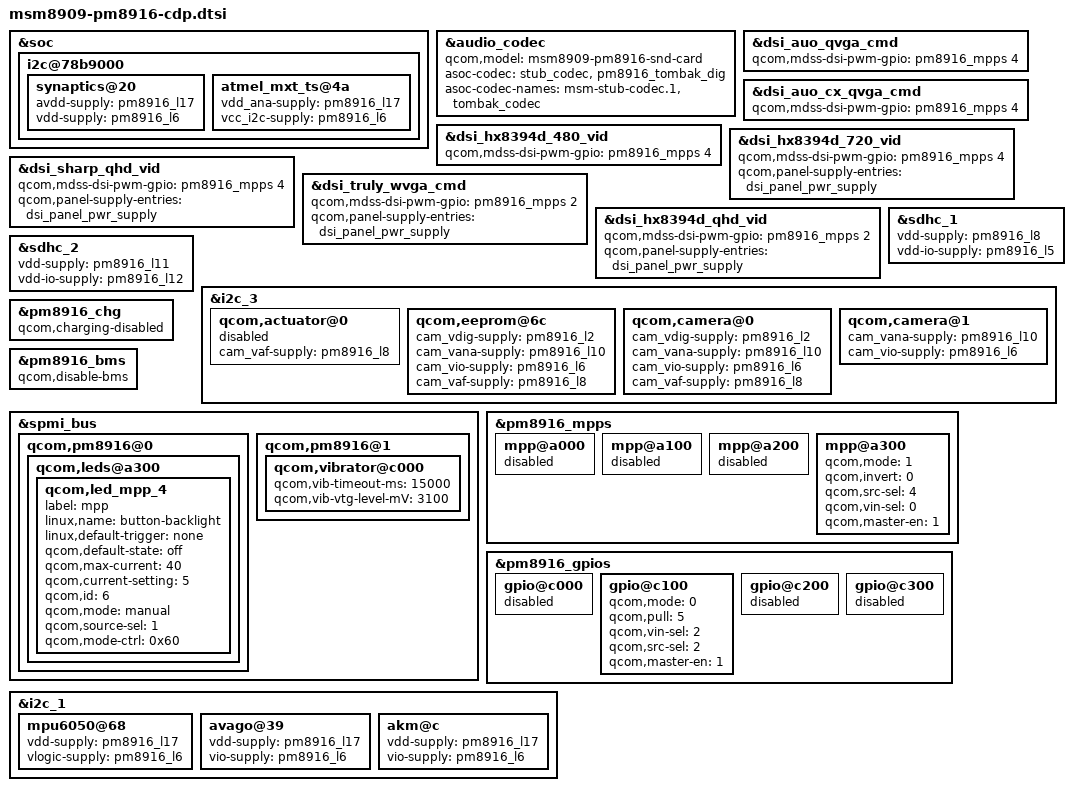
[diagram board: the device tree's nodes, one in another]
/*
 * Copyright (c) 2014-2016, 2017, The Linux Foundation. All rights reserved.
 *
 * This program is free software; you can redistribute it and/or modify
 * it under the terms of the GNU General Public License version 2 and
 * only version 2 as published by the Free Software Foundation.
 *
 * This program is distributed in the hope that it will be useful,
 * but WITHOUT ANY WARRANTY; without even the implied warranty of
 * MERCHANTABILITY or FITNESS FOR A PARTICULAR PURPOSE.  See the
 * GNU General Public License for more details.
 */

#include "msm8909-pm8916.dtsi"
#include "msm8909-pinctrl.dtsi"

&soc {
	i2c@78b9000 {
		synaptics@20 {
			avdd-supply = <&pm8916_l17>;
			vdd-supply = <&pm8916_l6>;
		};

		atmel_mxt_ts@4a {
			vdd_ana-supply = <&pm8916_l17>;
			vcc_i2c-supply = <&pm8916_l6>;
		};
	};

};

&audio_codec {
	status = "ok";
	qcom,model = "msm8909-pm8916-snd-card";
	asoc-codec = <&stub_codec>, <&pm8916_tombak_dig>;
	asoc-codec-names = "msm-stub-codec.1", "tombak_codec";
};

&dsi_auo_qvga_cmd {
	qcom,mdss-dsi-pwm-gpio = <&pm8916_mpps 4 0>;
};

&dsi_auo_cx_qvga_cmd {
	qcom,mdss-dsi-pwm-gpio = <&pm8916_mpps 4 0>;
};

&dsi_hx8394d_480_vid {
	qcom,mdss-dsi-pwm-gpio = <&pm8916_mpps 4 0>;
};

&dsi_hx8394d_720_vid {
	qcom,mdss-dsi-pwm-gpio = <&pm8916_mpps 4 0>;
	qcom,panel-supply-entries = <&dsi_panel_pwr_supply>;
};

&dsi_sharp_qhd_vid {
	qcom,mdss-dsi-pwm-gpio = <&pm8916_mpps 4 0>;
	qcom,panel-supply-entries = <&dsi_panel_pwr_supply>;
};

&dsi_truly_wvga_cmd {
	qcom,mdss-dsi-pwm-gpio = <&pm8916_mpps 2 0>;
	qcom,panel-supply-entries = <&dsi_panel_pwr_supply>;
};

&dsi_hx8394d_qhd_vid {
	qcom,mdss-dsi-pwm-gpio = <&pm8916_mpps 2 0>;
	qcom,panel-supply-entries = <&dsi_panel_pwr_supply>;
};

&sdhc_1 {
	vdd-supply = <&pm8916_l8>;
	vdd-io-supply = <&pm8916_l5>;
};

&sdhc_2 {
	vdd-supply = <&pm8916_l11>;
	vdd-io-supply = <&pm8916_l12>;
};

&i2c_3 {
	qcom,actuator@0 {
		cam_vaf-supply = <&pm8916_l8>;
		status = "disabled";
	};


	qcom,eeprom@6c{
		cam_vdig-supply = <&pm8916_l2>;
		cam_vana-supply = <&pm8916_l10>;
		cam_vio-supply = <&pm8916_l6>;
		cam_vaf-supply = <&pm8916_l8>;
	};

	qcom,camera@0 {
		cam_vdig-supply = <&pm8916_l2>;
		cam_vana-supply = <&pm8916_l10>;
		cam_vio-supply = <&pm8916_l6>;
		cam_vaf-supply = <&pm8916_l8>;
	};

	qcom,camera@1 {
		cam_vana-supply = <&pm8916_l10>;
		cam_vio-supply = <&pm8916_l6>;
	};
};

&pm8916_chg {
	status = "ok";
	qcom,charging-disabled;
};

&pm8916_bms {
	status = "ok";
	qcom,disable-bms;
};

&spmi_bus {
	qcom,pm8916@0 {
		qcom,leds@a300 {
			status = "okay";
			qcom,led_mpp_4 {
				label = "mpp";
				linux,name = "button-backlight";
				linux,default-trigger = "none";
				qcom,default-state = "off";
				qcom,max-current = <40>;
				qcom,current-setting = <5>;
				qcom,id = <6>;
				qcom,mode = "manual";
				qcom,source-sel = <1>;
				qcom,mode-ctrl = <0x60>;
			};
		};
	};

	qcom,pm8916@1 {
		qcom,vibrator@c000 {
			status = "okay";
			qcom,vib-timeout-ms = <15000>;
			qcom,vib-vtg-level-mV = <3100>;
		};
	};
};

&pm8916_mpps {
	mpp@a000 { /* MPP 1 */
		/* VDD_PX */
		status = "disabled";
	};

	mpp@a100 { /* MPP 2 */
		/* HR LED */
		status = "disabled";
	};

	mpp@a200 { /* MPP 3 */
		/* VREF DAC */
		status = "disabled";
	};

	mpp@a300 { /* MPP 4 */
		/* Backlight PWM */
		qcom,mode = <1>;		/* Digital output */
		qcom,invert = <0>;		/* Disable invert */
		qcom,src-sel = <4>;		/* DTEST1 */
		qcom,vin-sel = <0>;		/* VPH_PWR */
		qcom,master-en = <1>;		/* Enable MPP */
	};
};

&pm8916_gpios {
	gpio@c000 { /* GPIO 1 */
		/* Battery UICC Alarm */
		status = "disabled";
	};

	gpio@c100 { /* GPIO 2 */
		/* NFC_CLK_REQ */
		qcom,mode = <0>; /* QPNP_PIN_MODE_DIG_IN */
		qcom,pull = <5>; /* QPNP_PIN_PULL_NO */
		qcom,vin-sel = <2>; /* QPNP_PIN_VIN2 */
		qcom,src-sel = <2>; /* QPNP_PIN_SEL_FUNC_1 */
		qcom,master-en = <1>;
	};

	gpio@c200 { /* GPIO 3 */
		/* External regulator control for WTR */
		status = "disabled";
	};

	gpio@c300 { /* GPIO 4 */
		/* External regulator control for APC */
		status = "disabled";
	};
};

&i2c_1 { /* BLSP1 QUP1 */
	mpu6050@68 { /* Gyroscope and accelerometer sensor combo */
		vdd-supply = <&pm8916_l17>;
		vlogic-supply = <&pm8916_l6>;
	};

	avago@39 { /* Ambient light and proximity sensor */
		vdd-supply = <&pm8916_l17>;
		vio-supply = <&pm8916_l6>;
	};

	akm@c { /* Magnetic field sensor */
		vdd-supply = <&pm8916_l17>;
		vio-supply = <&pm8916_l6>;
	};
};

